# STM32U5xx register map
File version: 1.3
Registers are 32-bit, read-write, reset 0x0 unless marked. A register's access mark holds for its fields unless they carry their own. Offsets are from the block's base; [hi:lo] are bit positions; {n}, {i} and the like mark numbered series; 'fields as' and 'values as' point back to an identical list.

## CRC — Cyclic redundancy check calculation unit
Base 0x40023000
Same registers: SEC_CRC 0x50023000
0x00 DR reset 0xFFFFFFFF — Data register
  [31:0] DR — Data register bits
0x04 IDR — Independent data register
  [31:0] IDR — General-purpose 8-bit data register bits
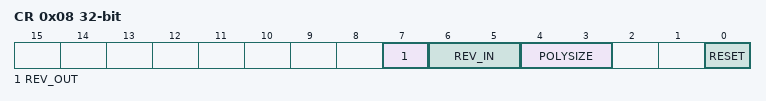
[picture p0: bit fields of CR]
0x08 CR — Control register
  [7] REV_OUT — Reverse output data
  [6:5] REV_IN — Reverse input data
  [4:3] POLYSIZE — Polynomial size
  [0] RESET — RESET bit
0x10 INIT reset 0xFFFFFFFF — Initial CRC value
  [31:0] CRC_INIT — Programmable initial CRC value
0x14 POL reset 0x4C11DB7 — polynomial
  [31:0] POL — Programmable polynomial

## CRS — Clock recovery system
Base 0x40006000
Same registers: SEC_CRS 0x50006000
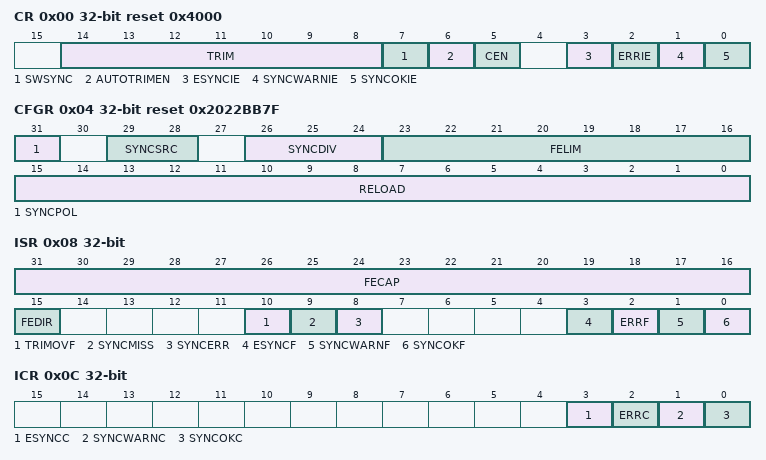
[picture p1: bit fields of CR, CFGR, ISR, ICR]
0x00 CR reset 0x4000 — control register
  [14:8] TRIM — HSI48 oscillator smooth trimming
  [7] SWSYNC — Generate software SYNC event
  [6] AUTOTRIMEN — Automatic trimming enable
  [5] CEN — Frequency error counter enable
  [3] ESYNCIE — Expected SYNC interrupt enable
  [2] ERRIE — Synchronization or trimming error interrupt enable
  [1] SYNCWARNIE — SYNC warning interrupt enable
  [0] SYNCOKIE — SYNC event OK interrupt enable
0x04 CFGR reset 0x2022BB7F — configuration register
  [31] SYNCPOL — SYNC polarity selection
  [29:28] SYNCSRC — SYNC signal source selection
  [26:24] SYNCDIV — SYNC divider
  [23:16] FELIM — Frequency error limit
  [15:0] RELOAD — Counter reload value
0x08 ISR ro — interrupt and status register
  [31:16] FECAP — Frequency error capture
  [15] FEDIR — Frequency error direction
  [10] TRIMOVF — Trimming overflow or underflow
  [9] SYNCMISS — SYNC missed
  [8] SYNCERR — SYNC error
  [3] ESYNCF — Expected SYNC flag
  [2] ERRF — Error flag
  [1] SYNCWARNF — SYNC warning flag
  [0] SYNCOKF — SYNC event OK flag
0x0C ICR — interrupt flag clear register
  [3] ESYNCC — Expected SYNC clear flag
  [2] ERRC — Error clear flag
  [1] SYNCWARNC — SYNC warning clear flag
  [0] SYNCOKC — SYNC event OK clear flag

## HASH — Hash processor
Base 0x420C0400
Same registers: SEC_HASH 0x520C0400
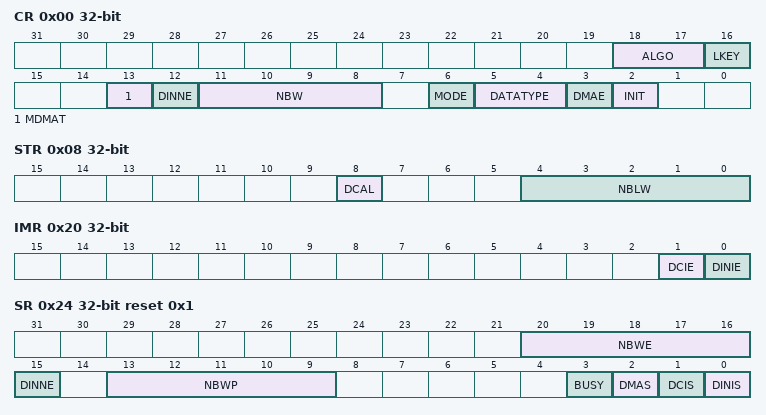
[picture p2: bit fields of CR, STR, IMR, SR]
0x00 CR access per field — control register
  [18:17] ALGO rw — Algorithm selection
  [16] LKEY rw — Long key selection
  [13] MDMAT rw — Multiple DMA Transfers
  [12] DINNE ro — DIN not empty
  [11:8] NBW ro — Number of words already pushed
  [6] MODE rw — Mode selection
  [5:4] DATATYPE rw — Data type selection
  [3] DMAE rw — DMA enable
  [2] INIT wo — Initialize message digest calculation
0x04 DIN wo — data input register
  [31:0] DATAIN — Data input
0x08 STR access per field — start register
  [8] DCAL wo — Digest calculation
  [4:0] NBLW rw — Number of valid bits in the last word of the message
{0xC+4i} HRA{i} ro (i=0..4) — HASH aliased digest register {i}
  [31:0] H{i}
0x20 IMR — interrupt enable register
  [1] DCIE — Digest calculation completion interrupt enable
  [0] DINIE — Data input interrupt enable
0x24 SR access per field reset 0x1 — status register
  [20:16] NBWE ro — Number of words expected
  [15] DINNE ro — DIN not empty
  [13:9] NBWP ro — Number of words already pushed
  [3] BUSY ro — Busy bit
  [2] DMAS ro — DMA Status
  [1] DCIS rw — Digest calculation completion interrupt status
  [0] DINIS rw — Data input interrupt status
{0xF8+4i} CSR{i} (i=0..53) — context swap registers
0x310 HR0 ro — digest register 0
  [31:0] H0
0x314 HR1 ro — digest register 1
  [31:0] H1
0x318 HR2 ro — digest register 4
  [31:0] H2
0x31C HR3 ro — digest register 3
  [31:0] H3
0x320 HR4 ro — digest register 4
  [31:0] H4
{0x310+4i} HR{i} ro (i=5..7) — supplementary digest register {i}
  [31:0] H{i}

## TAMP — Tamper and backup registers
Base 0x46007C00
Same registers: SEC_TAMP 0x56007C00
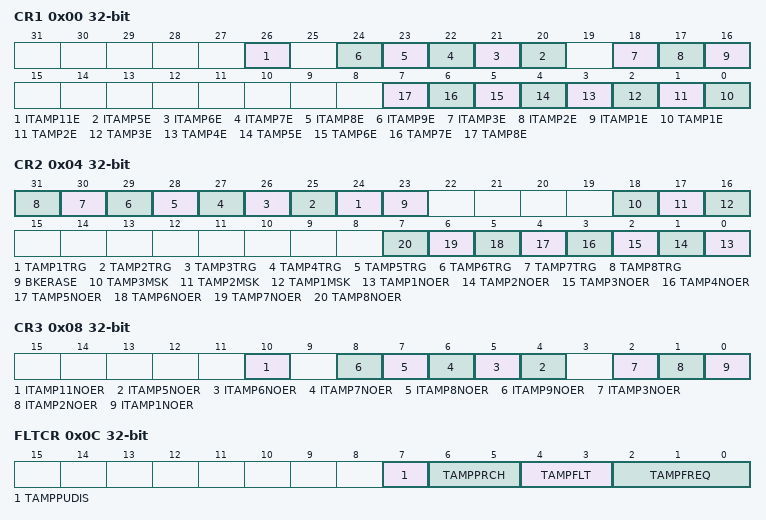
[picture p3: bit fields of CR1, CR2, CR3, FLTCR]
0x00 CR1 — control register 1
  [26] ITAMP11E — TAMP1E
  [n+15] ITAMP{n}E (n=5..9)
  [18] ITAMP3E
  [17] ITAMP2E
  [16] ITAMP1E
  [n-1] TAMP{n}E (n=1..8)
0x04 CR2 — control register 2
  [n+23] TAMP{n}TRG (n=1..8), [23] BKERASE, [18] TAMP3MSK, [17] TAMP2MSK, [16] TAMP1MSK, [n-1] TAMP{n}NOER (n=1..8)
0x08 CR3 — TAMP control register 3
  [10] ITAMP11NOER, [n-1] ITAMP{n}NOER (n=5..9), [2] ITAMP3NOER, [1] ITAMP2NOER, [0] ITAMP1NOER
0x0C FLTCR — TAMP filter control register
  [7] TAMPPUDIS, [6:5] TAMPPRCH, [4:3] TAMPFLT, [2:0] TAMPFREQ
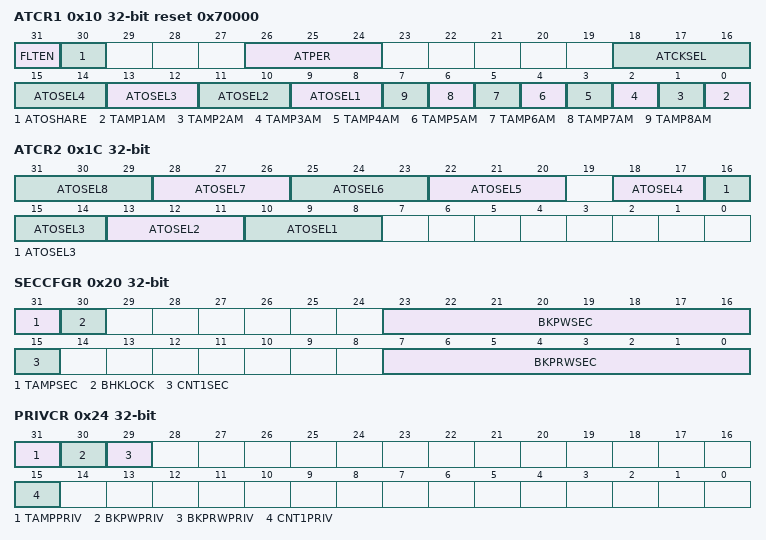
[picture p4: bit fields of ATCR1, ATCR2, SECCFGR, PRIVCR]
0x10 ATCR1 reset 0x70000 — TAMP active tamper control register
  [31] FLTEN — ATOSHARE
  [30] ATOSHARE
  [26:24] ATPER
  [18:16] ATCKSEL
  [2n+7:2n+6] ATOSEL{n} (n=1..4)
  [n-1] TAMP{n}AM (n=1..8)
0x14 ATSEEDR — TAMP active tamper seed register
  [31:0] SEED
0x1C ATCR2 — TAMP active tamper control register 2
  [3n+7:3n+5] ATOSEL{n} (n=5..8), [18:17] ATOSEL4, [16:14] ATOSEL3, [13:11] ATOSEL2, [10:8] ATOSEL1
0x20 SECCFGR — TAMP secure mode register
  [31] TAMPSEC, [30] BHKLOCK, [23:16] BKPWSEC, [15] CNT1SEC, [7:0] BKPRWSEC
0x24 PRIVCR — TAMP privilege mode control register
  [31] TAMPPRIV, [30] BKPWPRIV, [29] BKPRWPRIV, [15] CNT1PRIV
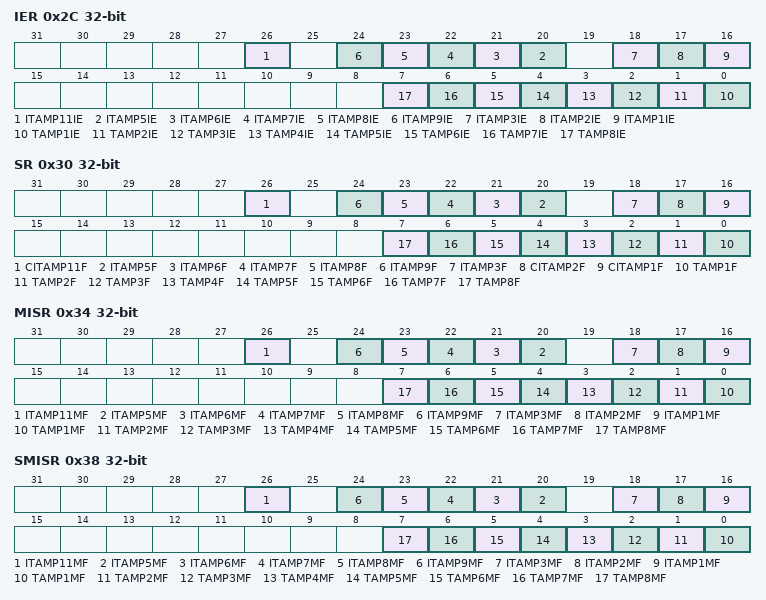
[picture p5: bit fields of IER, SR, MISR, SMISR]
0x2C IER — TAMP interrupt enable register
  [26] ITAMP11IE, [n+15] ITAMP{n}IE (n=5..9), [18] ITAMP3IE, [17] ITAMP2IE, [16] ITAMP1IE, [n-1] TAMP{n}IE (n=1..8)
0x30 SR ro — TAMP status register
  [26] CITAMP11F, [n+15] ITAMP{n}F (n=5..9), [18] ITAMP3F, [17] CITAMP2F, [16] CITAMP1F, [n-1] TAMP{n}F (n=1..8)
0x34 MISR ro — TAMP masked interrupt status register
  [26] ITAMP11MF, [n+15] ITAMP{n}MF (n=5..9), [18] ITAMP3MF, [17] ITAMP2MF, [16] ITAMP1MF, [n-1] TAMP{n}MF (n=1..8)
0x38 SMISR ro — TAMP secure masked interrupt status register
  fields as MISR
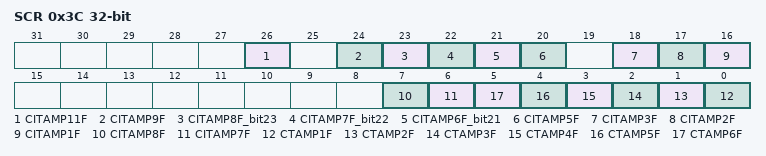
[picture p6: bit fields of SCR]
0x3C SCR — TAMP status clear register
  [26] CITAMP11F
  [24] CITAMP9F
  [23] CITAMP8F_bit23
  [22] CITAMP7F_bit22
  [21] CITAMP6F_bit21
  [20] CITAMP5F
  [18] CITAMP3F
  [17] CITAMP2F
  [16] CITAMP1F
  [7] CITAMP8F — CITAMP3F
  [6] CITAMP7F — CITAMP3F
  [n-1] CTAMP{n}F (n=1..6)
0x40 COUNT1R ro — TAMP monotonic counter 1register
  [31:0] COUNT
0x50 OR — TAMP option registe
  [0] VCOREMEN
{0x100+4i} BKP{i}R (i=0..31) — TAMP backup register
  [31:0] BKP
